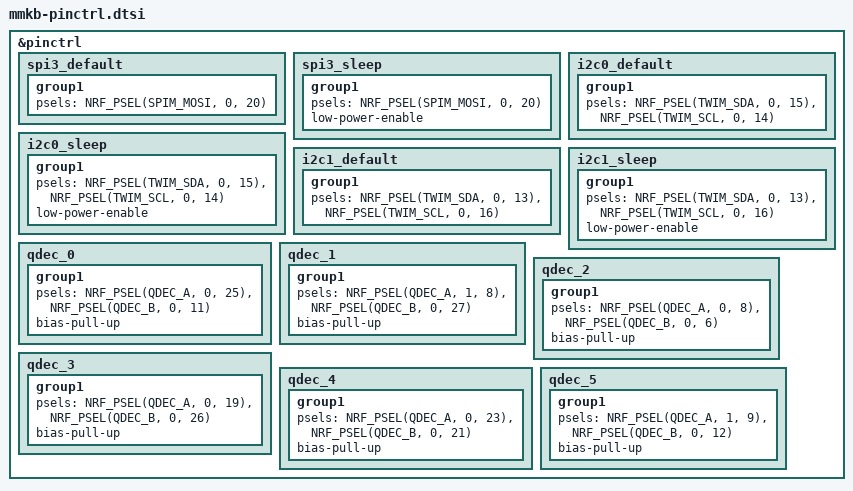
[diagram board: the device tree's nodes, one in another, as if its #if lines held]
/*
 * copyright (c) 2024 ZMK project contributors
 *
 * SPDX-license-identifier: MIT
 */

// uncomment exactly one board revision to use
// #define REV_3 TRUE
#define REV_2 TRUE

&pinctrl {
    
    // 1-wire SPI for RGB underglow
    spi3_default: spi3_default {
        group1 {
            psels = <NRF_PSEL(SPIM_MOSI, 0, 20)>;
        };
    };

    spi3_sleep: spi3_sleep {
        group1 {
            psels = <NRF_PSEL(SPIM_MOSI, 0, 20)>;
            low-power-enable;
        };
    };

    #ifdef REV_3
    // I2C for display (REV_3)
    i2c0_default: i2c0_default {
        group1 {
            psels = <NRF_PSEL(TWIM_SDA, 0, 15)>,
                    <NRF_PSEL(TWIM_SCL, 0, 14)>;
        };
    };

    i2c0_sleep: i2c0_sleep {
        group1 {
            psels = <NRF_PSEL(TWIM_SDA, 0, 15)>,
                    <NRF_PSEL(TWIM_SCL, 0, 14)>;
            low-power-enable;
        };
    };

    #elif defined(REV_2)
    // I2C for display (REV_2, bridged pins workaround)
    i2c0_default: i2c0_default {
        group1 {
            psels = <NRF_PSEL(TWIM_SDA, 0, 15)>,
                    <NRF_PSEL(TWIM_SCL, 0, 22)>;
        };
    };

    i2c0_sleep: i2c0_sleep {
        group1 {
            psels = <NRF_PSEL(TWIM_SDA, 0, 15)>,
                    <NRF_PSEL(TWIM_SCL, 0, 22)>;
            low-power-enable;
        };
    };
    #endif

    // I2C for fuel gauge chip
    i2c1_default: i2c1_default {
        group1 {
            psels = <NRF_PSEL(TWIM_SDA, 0, 13)>,
                    <NRF_PSEL(TWIM_SCL, 0, 16)>;
        };
    };

    i2c1_sleep: i2c1_sleep {
        group1 {
            psels = <NRF_PSEL(TWIM_SDA, 0, 13)>,
                    <NRF_PSEL(TWIM_SCL, 0, 16)>;
            low-power-enable;
        };
    };

    // quadrature rotary encoders
    qdec_0: qdec_0 {
        group1 {
            psels = <NRF_PSEL(QDEC_A, 0, 25)>,
                    <NRF_PSEL(QDEC_B, 0, 11)>;
            bias-pull-up;
        };
    };

    qdec_1: qdec_1 {
        group1 {
            psels = <NRF_PSEL(QDEC_A, 1, 8)>,
                    <NRF_PSEL(QDEC_B, 0, 27)>;
            bias-pull-up;
        };
    };

    qdec_2: qdec_2 {
        group1 {
            psels = <NRF_PSEL(QDEC_A, 0, 8)>,
                    <NRF_PSEL(QDEC_B, 0, 6)>;
            bias-pull-up;
        };
    };

    qdec_3: qdec_3 {
        group1 {
            psels = <NRF_PSEL(QDEC_A, 0, 19)>,
                    <NRF_PSEL(QDEC_B, 0, 26)>;
            bias-pull-up;
        };
    };

    qdec_4: qdec_4 {
        group1 {
            psels = <NRF_PSEL(QDEC_A, 0, 23)>,
                    <NRF_PSEL(QDEC_B, 0, 21)>;
            bias-pull-up;
        };
    };

    qdec_5: qdec_5 {
        group1 {
            psels = <NRF_PSEL(QDEC_A, 1, 9)>,
                    <NRF_PSEL(QDEC_B, 0, 12)>;
            bias-pull-up;
        };
    };
};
